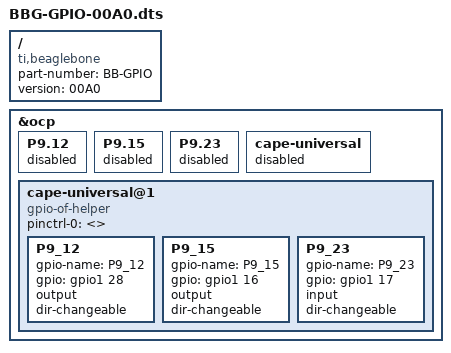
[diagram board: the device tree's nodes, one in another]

/dts-v1/;
/plugin/;

#include <dt-bindings/board/am335x-bbw-bbb-base.h>
#include <dt-bindings/gpio/gpio.h>
#include <dt-bindings/pinctrl/am33xx.h>

/ {
	compatible = "ti,beaglebone", "ti,beaglebone-black", "ti,beaglebone-green";

	/* identification */
	part-number = "BB-GPIO";
	version = "00A0";		

	/*
	* Free up the pins used by the cape from the pinmux helpers.
	*/
	fragment@0 {
	target = <&ocp>; 
		__overlay__ {
			P9.12 { status = "disabled"; }; /* GPIO_60, out */
			P9.15 { status = "disabled"; }; /* GPIO_48, out */
			P9.23 { status = "disabled"; }; /* GPIO_49, in  */
		};
	};
	
	/*
	* Free up the gpios used by the cape-universal gpio helpers.
 	*/
	fragment@1 {
		target = <&ocp>;
  			__overlay__ {
  			cape-universal { status = "disabled"; };
    		};
	};
	
	/*
	 * Make a new set of gpio helpers.
	 */
	 fragment@2 {
		target = <&ocp>;
		__overlay__ {
			cape-universal@1 {
				compatible = "gpio-of-helper";
				status = "okay";
				pinctrl-names = "default";
				pinctrl-0 = <>;

				P9_12 {
					gpio-name = "P9_12";
					gpio = <&gpio1 28 0>;
					output;
					dir-changeable;
				};
				P9_15 {
					gpio-name = "P9_15";
					gpio = <&gpio1 16 0>;
					output;
					dir-changeable;
				};
				P9_23 {
					gpio-name = "P9_23";
					gpio = <&gpio1 17 0>;
					input;
					dir-changeable;
				};
			};
		};
	};
};
